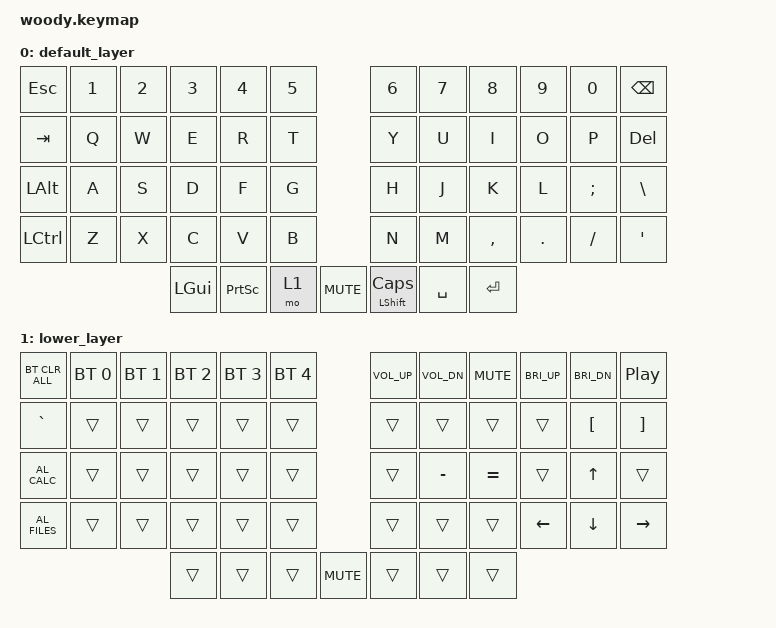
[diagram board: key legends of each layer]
#include <behaviors.dtsi>
#include <dt-bindings/zmk/keys.h>
#include <dt-bindings/zmk/bt.h>

/ {
    keymap {
        compatible = "zmk,keymap";

        default_layer {

            bindings = <
&kp ESC     &kp N1      &kp N2      &kp N3      &kp N4      &kp N5                  &kp N6          &kp N7      &kp N8    &kp N9    &kp N0      &kp BSPC
&kp TAB     &kp Q       &kp W       &kp E       &kp R       &kp T                   &kp Y           &kp U       &kp I     &kp O     &kp P       &kp DEL
&kp LALT    &kp A       &kp S       &kp D       &kp F       &kp G                   &kp H           &kp J       &kp K     &kp L     &kp SEMICOLON      &kp BSLH
&kp LCTRL   &kp Z       &kp X       &kp C       &kp V       &kp B                   &kp N           &kp M       &kp COMMA &kp DOT   &kp FSLH    &kp SQT
                                    &kp LGUI    &kp PSCRN   &mo 1   &kp C_MUTE      &mt LSHFT CAPS  &kp SPACE   &kp ENTER

            >;
            sensor-bindings = <&inc_dec_kp C_VOL_UP C_VOL_DN>;
        };

        lower_layer {
            bindings = <
&bt BT_CLR_ALL  &bt BT_SEL 0 &bt BT_SEL 1 &bt BT_SEL 2 &bt BT_SEL 3 &bt BT_SEL 4        &kp C_VOL_UP&kp C_VOL_DN&kp C_MUTE  &kp C_BRI_UP&kp C_BRI_DN&kp C_PP
&kp GRAVE       &trans      &trans      &trans      &trans      &trans                  &trans      &trans      &trans      &trans      &kp LBKT    &kp RBKT
&kp C_AL_CALC   &trans      &trans      &trans      &trans      &trans                  &trans      &kp MINUS   &kp EQUAL   &trans      &kp UP      &trans
&kp C_AL_FILES  &trans      &trans      &trans      &trans      &trans                  &trans      &trans      &trans      &kp LEFT    &kp DOWN    &kp RIGHT
                                        &trans      &trans      &trans  &kp C_MUTE      &trans      &trans      &trans
            >;
            sensor-bindings = <&inc_dec_kp C_VOL_UP C_VOL_DN>;
        };
    };
};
